AUTOSAR XML (schema 4-0-3)
standard types defined: uint8, UInt32, UInt8
package /AUTOSAR_Platform/DataConstrs
  range DC_UInt8: raw 0..255
package /PATAC/MSM/ComponentTypes
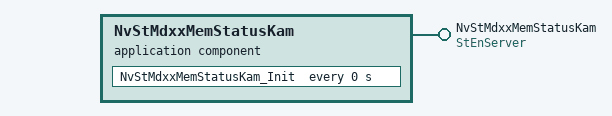
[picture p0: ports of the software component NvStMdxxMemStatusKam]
  application sw component type NvStMdxxMemStatusKam
    provide port NvStMdxxMemStatusKam: provided-com-specs=[{operation=Clear, queue-length=1}, {operation=Get, queue-length=1}, {operation=Set, queue-length=1}], provided-interface=StEnServer
    behavior NvStMdxxMemStatusKam_InternalBehavior
      operation invoked event NvStMdxxMemStatusKam_Clear: start-on-event=NvStMdxxMemStatusKam_Clear, operation=NvStMdxxMemStatusKam.Clear
      operation invoked event NvStMdxxMemStatusKam_Get: start-on-event=NvStMdxxMemStatusKam_Get, operation=NvStMdxxMemStatusKam.Get
      timing event NvStMdxxMemStatusKam_Init_1_InitEvent: start-on-event=NvStMdxxMemStatusKam_Init, period=0
      operation invoked event NvStMdxxMemStatusKam_Set: start-on-event=NvStMdxxMemStatusKam_Set, operation=NvStMdxxMemStatusKam.Set
      4 x runnable:
        NvStMdxxMemStatusKam_Clear
        NvStMdxxMemStatusKam_Get
        NvStMdxxMemStatusKam_Init
        NvStMdxxMemStatusKam_Set
  swc implementation NvStMdxxMemStatusKam_Implementation: behavior=NvStMdxxMemStatusKam_InternalBehavior
    code-descriptors:
      code Default: artifact-descriptors=autosar-engineering-object={short-label=Default, category=SWSRC}
package /PATAC/MSM/ModeAdjust/PortInterface
  client server interface StEnServer
    operation Clear
      arg data: type=UInt8, direction=IN, server-argument-impl-policy=USE-ARGUMENT-TYPE
    operation Get
      arg data: type=UInt32, direction=OUT, server-argument-impl-policy=USE-ARGUMENT-TYPE
    operation Set
      arg data: type=UInt8, direction=IN, server-argument-impl-policy=USE-ARGUMENT-TYPE
